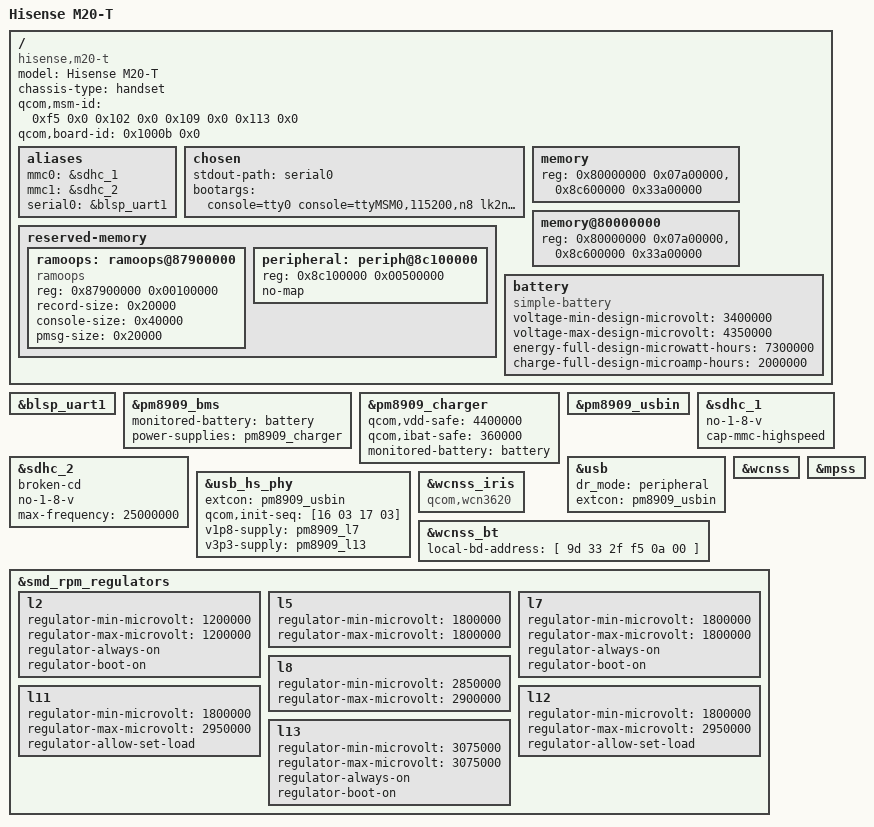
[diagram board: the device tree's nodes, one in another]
// SPDX-License-Identifier: GPL-2.0-only
/*
 * Hisense M20-T (Uniscope ODM, MSM8909 + PM8909).
 *
 * Headless port: no display/touch/audio/keypad -- the device serves as a
 * boot-and-serve mini rootfs host (Alpine armhf) with WiFi + SSH.
 *
 * Root node qcom,msm-id / qcom,board-id are copied verbatim from the stock
 * bootloader's DT blob (the entry the stock aboot actually selects for this
 * hardware: "MSM8909-PM8909 1GB QRD SKUA", soc_id=245/0xf5,
 * platform_version=0x10000, hw_platform=QRD, subtype=0), because the stock
 * aboot (not lk2nd) picks the DTB by matching these ids against SMEM values.
 *
 * USB controller is ci-hdrc; WiFi = wcn3620; PMIC = PM8909.
 */

/dts-v1/;

#include "qcom-msm8909-pm8909.dtsi"

#include <dt-bindings/gpio/gpio.h>

/ {
	model = "Hisense M20-T";
	compatible = "hisense,m20-t", "qcom,msm8909";
	chassis-type = "handset";

	/* Stock bootloader DT-matching ids (see comment above). */
	qcom,msm-id = <0xf5 0x0 0x102 0x0 0x109 0x0 0x113 0x0>;
	qcom,board-id = <0x1000b 0x0>;

	aliases {
		mmc0 = &sdhc_1;
		mmc1 = &sdhc_2;
		serial0 = &blsp_uart1;
	};

	chosen {
		stdout-path = "serial0";
		bootargs = "console=tty0 console=ttyMSM0,115200,n8 lk2nd.pass-simplefb lk2nd.pass-ramoops earlycon panic=0";
	};

	/*
	 * MSM8909 Hisense M20-T Physical Memory Map:
	 * Verified directly from live Android 4.4 /proc/iomem and dmesg:
	 * Bank 0:  0x80000000 - 0x878fffff (121 MB System RAM)
	 * Ramoops: 0x87900000 - 0x879fffff (1 MB in Lowmem! 100% readable by /dev/mem!)
	 * TZ-apps: 0x87a00000 - 0x87bfffff (2 MB, from qcom-msm8909.dtsi)
	 * RMTFS+:  0x87c00000 - 0x87ffffff (4 MB, from qcom-msm8909.dtsi)
	 * Modem:   0x88000000 - 0x8c0fffff (65 MB Modem ADSP)
	 * Pronto:  0x8c100000 - 0x8c5fffff (5 MB Pronto WCNSS subsystem)
	 * Bank 1:  0x8c600000 - 0xbfffffff (826 MB System RAM)
	 */
	memory {
		device_type = "memory";
		reg = <0x80000000 0x07a00000>,
		      <0x8c600000 0x33a00000>;
	};

	memory@80000000 {
		device_type = "memory";
		reg = <0x80000000 0x07a00000>,
		      <0x8c600000 0x33a00000>;
	};

	reserved-memory {
		#address-cells = <1>;
		#size-cells = <1>;
		ranges;

		/* Ramoops / PStore in Lowmem (1MB at 0x87900000, outside tz-apps) */
		ramoops: ramoops@87900000 {
			compatible = "ramoops";
			reg = <0x87900000 0x00100000>;
			record-size = <0x20000>;
			console-size = <0x40000>;
			pmsg-size = <0x20000>;
		};

		/* Peripheral/Pronto subsystem (5MB) - TrustZone protected */
		peripheral: periph@8c100000 {
			reg = <0x8c100000 0x00500000>;
			no-map;
		};
	};

	battery: battery {
		compatible = "simple-battery";
		voltage-min-design-microvolt = <3400000>;
		voltage-max-design-microvolt = <4350000>;
		energy-full-design-microwatt-hours = <7300000>;
		charge-full-design-microamp-hours = <2000000>;
	};
};

&blsp_uart1 {
	status = "okay";
};

&pm8909_bms {
	monitored-battery = <&battery>;
	power-supplies = <&pm8909_charger>;
	status = "okay";
};

&pm8909_charger {
	qcom,vdd-safe = <4400000>;
	qcom,ibat-safe = <360000>;

	monitored-battery = <&battery>;

	status = "okay";
};

&pm8909_usbin {
	status = "okay";
};

&sdhc_1 {
	/delete-property/ mmc-hs200-1_8v;
	/delete-property/ mmc-ddr-1_8v;
	no-1-8-v;
	cap-mmc-highspeed;
	status = "okay";
};

&sdhc_2 {
	broken-cd;
	no-1-8-v;
	/* SD tuning: 4-bit works only at a capped clock — 1-bit verified OK,
	   full speed failed. Re-enable cap-sd-highspeed once timing is tuned. */
	max-frequency = <25000000>;
	status = "okay";
};

&usb {
	dr_mode = "peripheral";
	extcon = <&pm8909_usbin>;
	status = "okay";
};

&usb_hs_phy {
	extcon = <&pm8909_usbin>;
	qcom,init-seq = [16 03 17 03];
	v1p8-supply = <&pm8909_l7>;
	v3p3-supply = <&pm8909_l13>;
};

&wcnss {
	status = "okay";
};

&wcnss_iris {
	compatible = "qcom,wcn3620";
	status = "okay";
};

&wcnss_bt {
	/* LSB-first per the kernel qca convention; displays as 00:0A:F5:2F:33:9D */
	local-bd-address = [ 9d 33 2f f5 0a 00 ];
	status = "okay";
};

&smd_rpm_regulators {
	l2 {
		regulator-min-microvolt = <1200000>;
		regulator-max-microvolt = <1200000>;
		regulator-always-on;
		regulator-boot-on;
	};

	l5 {
		regulator-min-microvolt = <1800000>;
		regulator-max-microvolt = <1800000>;
	};

	l7 {
		regulator-min-microvolt = <1800000>;
		regulator-max-microvolt = <1800000>;
		regulator-always-on;
		regulator-boot-on;
	};

	l8 {
		regulator-min-microvolt = <2850000>;
		regulator-max-microvolt = <2900000>;
	};

	l11 {
		regulator-min-microvolt = <1800000>;
		regulator-max-microvolt = <2950000>;
		regulator-allow-set-load;
	};

	l12 {
		regulator-min-microvolt = <1800000>;
		regulator-max-microvolt = <2950000>;
		regulator-allow-set-load;
	};

	l13 {
		regulator-min-microvolt = <3075000>;
		regulator-max-microvolt = <3075000>;
		regulator-always-on;
		regulator-boot-on;
	};
};

/* Cellular modem subsystem (qcom_q6v5_mss): firmware in /lib/firmware
 * (mba.mbn, modem.mdt + modem.bXX from the modem partition). */
&mpss {
	status = "okay";
};
